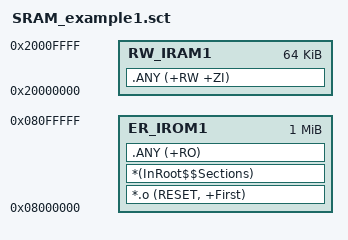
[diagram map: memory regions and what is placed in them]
; *************************************************************
; *** Scatter-Loading Description File generated by uVision ***
; *************************************************************

; 加载域名 (基地址 | ("+" 地址偏移)) [属性列表] [最大容量]  方括号中的为选填内容
LR_IROM1 0x08000000 0x00100000 {        ; 注释: 加载域，基地址 空间大小
    ; 执行区域描述 +

    ; 执行域名 (基地址 | "+" 地址偏移) [属性列表] [最大容量 ]   方括号中的为选填内容
    ER_IROM1 0x08000000 0x00100000 {        ; 注释: 加载地址 = 执行地址
        ; 输入节区描述

        ; 模块选择样式 "(" 输入节区样式 "," "+" 输入节区属性")"
        ; 模块选择样式 "(" 输入节区样式 "," "+" 节区特性")"
        ; 模块选择样式 "(" 输入符号样式 "," "+" 节区特性")"
        ; 模块选择样式 "(" 输入符号样式 "," "+" 输入节区属性")"
        *.o (RESET, +First)                     ; 使用语句“.o”可以选择所有 o 文件
        *(InRoot$$Sections)
        .ANY (+RO)                              ; 使用 “*” 或 “.ANY” 可以选择所有的 o 文件及 lib 文件
    }

    RW_IRAM1 0x20000000 0x00010000 {    ; 注释: 可读写数据
        .ANY (+RW +ZI)
    }
}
